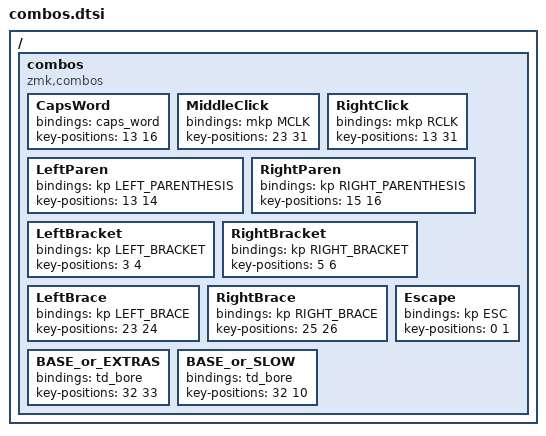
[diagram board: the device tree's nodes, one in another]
// ╭──────┬──────┬──────┬──────┬──────╮                ╭──────┬──────┬──────┬──────┬──────╮
//    00     01     02     03    04                       05     06     07     08     09
// ├──────┼──────┼──────┼──────┼──────┤                ├──────┼──────┼──────┼──────┼──────┤
//    10     11     12     13    14                       15     16     17     18     19
// ├──────┼──────┼──────┼──────┼──────┤                ├──────┼──────┼──────┼──────┼──────┤
//    20     21     22     23    24                       25     26     27     28     29
// ╰──────┴──────┴──────┼──────┼──────┼──────╮  ╭──────┼──────┼──────┴──────┴──────┴──────╯
//                         30     31     32        33     34     35
//                      ╰──────┴──────┴──────╯  ╰──────┴──────┴──────╯

/ {
    combos {
        compatible = "zmk,combos";

        CapsWord {
            bindings = <&caps_word>;
            key-positions = <13 16>;
        };

        MiddleClick {
            bindings = <&mkp MCLK>;
            key-positions = <23 31>;
        };

        RightClick {
            bindings = <&mkp RCLK>;
            key-positions = <13 31>;
        };

        LeftParen {
            bindings = <&kp LEFT_PARENTHESIS>;
            key-positions = <13 14>;
        };

        RightParen {
            bindings = <&kp RIGHT_PARENTHESIS>;
            key-positions = <15 16>;
        };

        LeftBracket {
            bindings = <&kp LEFT_BRACKET>;
            key-positions = <3 4>;
        };

        RightBracket {
            bindings = <&kp RIGHT_BRACKET>;
            key-positions = <5 6>;
        };

        LeftBrace {
            bindings = <&kp LEFT_BRACE>;
            key-positions = <23 24>;
        };

        RightBrace {
            bindings = <&kp RIGHT_BRACE>;
            key-positions = <25 26>;
        };

        Escape {
            bindings = <&kp ESC>;
            key-positions = <0 1>;
        };

        BASE_or_EXTRAS {
            bindings = <&td_bore>;
            key-positions = <32 33>;
        };

        BASE_or_SLOW {
            bindings = <&td_bore>;
            key-positions = <32 10>;
        };
    };
};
